# RS1xxxx register map
Vendor: Silicon Lab Inc.; Series: ARMCM4; File version: 1.2
CPU: CM4 r1p0, little endian, MPU, FPU, 6 interrupt priority bits
Registers are 32-bit, read-write, reset 0x0 unless marked. A register's access mark holds for its fields unless they carry their own. Offsets are from the block's base; [hi:lo] are bit positions; lines under a group give offsets from that group; {n}, {i} and the like mark numbered series.

## SDC — Sensor Data Collector Register structure
Base 0x24042400
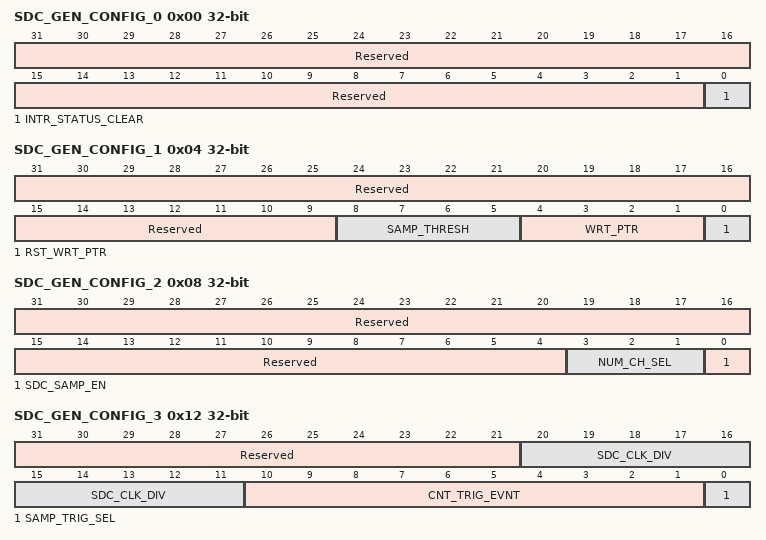
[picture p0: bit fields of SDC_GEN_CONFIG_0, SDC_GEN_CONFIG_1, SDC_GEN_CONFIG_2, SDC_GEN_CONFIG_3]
0x00 SDC_GEN_CONFIG_0 — SDC general configuration 0
  [31:1] Reserved — Reserevd
  [0] INTR_STATUS_CLEAR — Writing 1 clears interrupt, reading gives SDC Interrupt status
0x04 SDC_GEN_CONFIG_1 — SDC general configuration 1
  [31:9] Reserved — Reserevd
  [8:5] SAMP_THRESH — Number of data sampled to be collected from Aux-ADC and stored in Buffer before interrupt is raised/wakeup is initialed
  [4:1] WRT_PTR ro — Write pointer Value
  [0] RST_WRT_PTR — Writing 1 will resets the write pointer so that new samples can be filled in Buffer.
0x08 SDC_GEN_CONFIG_2 — SDC general configuration 2
  [31:4] Reserved — Reserevd
  [3:1] NUM_CH_SEL — Number of Channels to be used
  [0] SDC_SAMP_EN — SDC Data Sampling mode
    1=Enable; 0=Disable
0x12 SDC_GEN_CONFIG_3 — SDC general configuration 3
  [31:21] Reserved — Reserevd
  [20:11] SDC_CLK_DIV — SDCSS clock division factor
  [10:1] CNT_TRIG_EVNT — which trigger event AUX-ADC Data will sampled
    1=Enable; 0=Disable
  [0] SAMP_TRIG_SEL — select the trigger event on which AUX-ADC Data is sampled
    1=Enable; 0=Disable
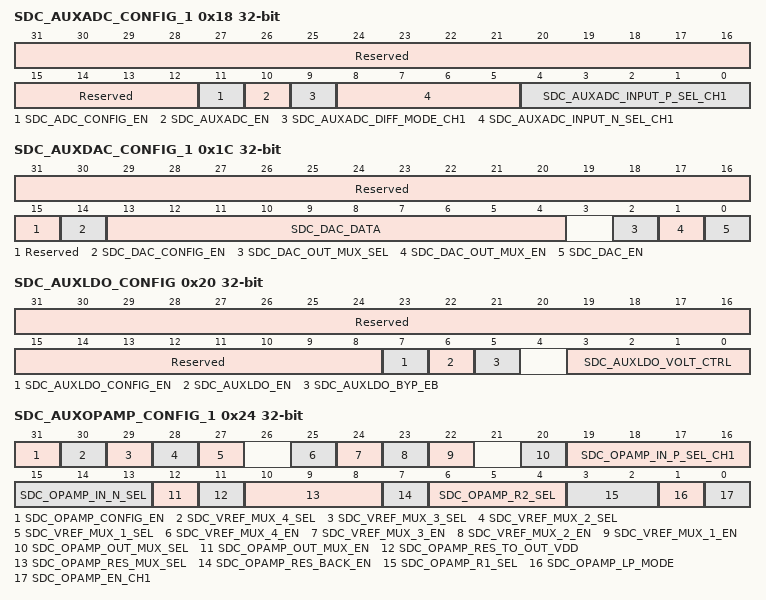
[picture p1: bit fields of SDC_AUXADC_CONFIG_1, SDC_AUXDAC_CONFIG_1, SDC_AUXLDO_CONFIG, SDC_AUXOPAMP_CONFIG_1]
0x18 SDC_AUXADC_CONFIG_1 — SDC AUX ADC configuration 1
  [31:12] Reserved — Reserevd
  [11] SDC_ADC_CONFIG_EN — On Enabling this register, SDC ADC Configuration will be Applied.
  [10] SDC_AUXADC_EN — AUXADC Enable from SDC Block
  [9] SDC_AUXADC_DIFF_MODE_CH1 — Enable Differential Mode in AUX ADC for Channel -1
  [8:5] SDC_AUXADC_INPUT_N_SEL_CH1 — AUXADC's Negative Input Mux Select for Channel-1
  [4:0] SDC_AUXADC_INPUT_P_SEL_CH1 — AUXADC's Positive Input Mux Select for Channel-1
0x1C SDC_AUXDAC_CONFIG_1 — SDC AUX DAC configuration 1
  [31:15] Reserved — Reserevd
  [14] SDC_DAC_CONFIG_EN — On Enabling this register, SDC DAC Configuration will be Applied.
  [13:4] SDC_DAC_DATA — SDC Aux DAC Data
  [2] SDC_DAC_OUT_MUX_SEL — Programming register for choosing GPIO in which DAC Output is connected
  [1] SDC_DAC_OUT_MUX_EN — Enable signal for Connecting DAC Output to GPIO
  [0] SDC_DAC_EN — Enable signal DAC
0x20 SDC_AUXLDO_CONFIG — SDC AUX LDO configuration
  [31:8] Reserved — Reserevd
  [7] SDC_AUXLDO_CONFIG_EN — SDC Aux LDO Configuration Control Enable
  [6] SDC_AUXLDO_EN — Turn-On AUX LDO
  [5] SDC_AUXLDO_BYP_EB — Configure AUXLDO in Buypass mode.When Enabled, Ouput supply of LDO will be same as Input supply.
  [3:0] SDC_AUXLDO_VOLT_CTRL — SDC AUX LDO Voltage Control Selection
0x24 SDC_AUXOPAMP_CONFIG_1 — SDC AUX OPAMP configuration 1
  [31] SDC_OPAMP_CONFIG_EN — On Enabling this register, SDC OPAMP Configuration will be Applied.
  [30] SDC_VREF_MUX_4_SEL — Selection register for choosing Voltage reference to external use on ULP_GPIO_15
  [29] SDC_VREF_MUX_3_SEL — Selection register for choosing Voltage reference to external use on ULP_GPIO_4
  [28] SDC_VREF_MUX_2_SEL — Selection register for choosing Voltage reference to external use on ULP_GPIO_3
  [27] SDC_VREF_MUX_1_SEL — Selection register for choosing Voltage reference to external use on ULP_GPIO_1
  [25] SDC_VREF_MUX_4_EN — Connect Low Drive Strength voltage reference for ULP GPIO 15 For external use
  [24] SDC_VREF_MUX_3_EN — Connect Low Drive Strength voltage reference for ULP GPIO 4 For external use
  [23] SDC_VREF_MUX_2_EN — Connect Low Drive Strength voltage reference for ULP GPIO 3 For external use
  [22] SDC_VREF_MUX_1_EN — Connect Low Drive Strength voltage reference for ULP GPIO 1 For external use
  [20] SDC_OPAMP_OUT_MUX_SEL — Configuration register for connecting OPAMP1 output to GPIO
  [19:16] SDC_OPAMP_IN_P_SEL_CH1 — Configuration register for selecting P Input of OPAMP1.,for CH1
  [15:13] SDC_OPAMP_IN_N_SEL — Configuration register for selecting N Input of OPAMP1.
  [12] SDC_OPAMP_OUT_MUX_EN — Configur this register to OPAMP1 Output will be connected to GPIO
  [11] SDC_OPAMP_RES_TO_OUT_VDD — Configuration register for Connecting R2 Resistor Ladder input
  [10:8] SDC_OPAMP_RES_MUX_SEL — Configuration register for Connecting R1 Resistor Ladder input
  [7] SDC_OPAMP_RES_BACK_EN — Configuration register for controlling Resistor Bank of OPAMP
  [6:4] SDC_OPAMP_R2_SEL — Configuration for Resistor Ladder R2 of OPAMP1 for controlling it gain.
  [3:2] SDC_OPAMP_R1_SEL — Configuration for Resistor Ladder R1 of OPAMP1 for controlling it gain.
  [1] SDC_OPAMP_LP_MODE — Configuration of OPAMP1 Operation mode
  [0] SDC_OPAMP_EN_CH1 — Enable signal for turning OPAMP to used for Channel-1 Operation
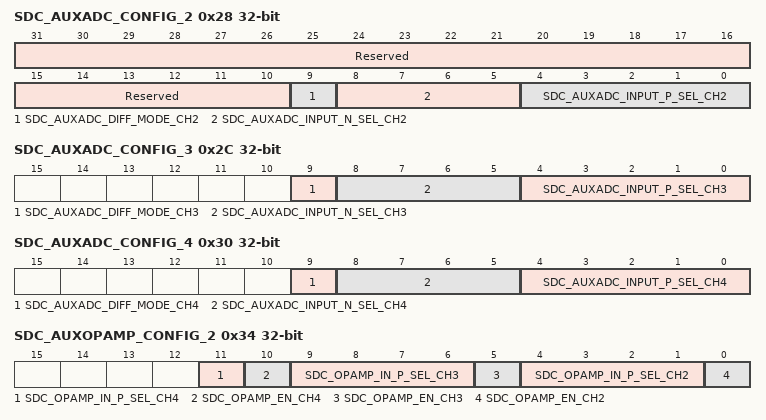
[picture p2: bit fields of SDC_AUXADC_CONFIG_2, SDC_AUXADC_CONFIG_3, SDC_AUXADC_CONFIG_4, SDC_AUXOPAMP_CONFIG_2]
0x28 SDC_AUXADC_CONFIG_2 — SDC AUX ADC configuration 2
  [31:10] Reserved — Reserevd
  [9] SDC_AUXADC_DIFF_MODE_CH2 — 1-AUX ADC Differencial mode, 0 - Single Ended Mode
  [8:5] SDC_AUXADC_INPUT_N_SEL_CH2 — AUXADC's Negative Input Mux Select for Channel-2
  [4:0] SDC_AUXADC_INPUT_P_SEL_CH2 — AUXADC's Positive Input Mux Select for Channel-2
0x2C SDC_AUXADC_CONFIG_3 — SDC AUX ADC configuration 3
  [9] SDC_AUXADC_DIFF_MODE_CH3 — 1-AUX ADC Differencial mode, 0 - Single Ended Mode
  [8:5] SDC_AUXADC_INPUT_N_SEL_CH3 — AUXADC's Negative Input Mux Select for Channel-3
  [4:0] SDC_AUXADC_INPUT_P_SEL_CH3 — AUXADC's Positive Input Mux Select for Channel-3
0x30 SDC_AUXADC_CONFIG_4 — SDC AUX ADC configuration 4
  [9] SDC_AUXADC_DIFF_MODE_CH4 — 1-AUX ADC Differencial mode, 0 - Single Ended Mode
  [8:5] SDC_AUXADC_INPUT_N_SEL_CH4 — AUXADC's Negative Input Mux Select for Channel-4
  [4:0] SDC_AUXADC_INPUT_P_SEL_CH4 — AUXADC's Positive Input Mux Select for Channel-4
0x34 SDC_AUXOPAMP_CONFIG_2 — SDC AUX OPAMP Configuration 2
  [11] SDC_OPAMP_IN_P_SEL_CH4 — Configuration register for selecting P Input of OPAMP1 for Channel-4
  [10] SDC_OPAMP_EN_CH4 — Enable signal for turning OPAMP to used for Channel-4 Operation
  [9:6] SDC_OPAMP_IN_P_SEL_CH3 — Configuration register for selecting P Input of OPAMP1 for Channel-3
  [5] SDC_OPAMP_EN_CH3 — Enable signal for turning OPAMP to used for Channel-4 Operation
  [4:1] SDC_OPAMP_IN_P_SEL_CH2 — Configuration register for selecting P Input of OPAMP1 for Channel-2
  [0] SDC_OPAMP_EN_CH2 — Enable signal for turning OPAMP to used for Channel-2 Operation
{0x38+4i} SDC_DATA_REGn[{i}] (i=0..15) group — SDC Data registers (0-15)
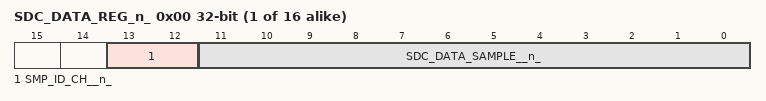
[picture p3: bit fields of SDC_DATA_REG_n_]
  0x00 SDC_DATA_REG_n_ ro reset not defined — SDC Data register _n_
    [13:12] SMP_ID_CH__n_ — Channel iD for sample _n_
    [11:0] SDC_DATA_SAMPLE__n_ — Sample 0 collected from Sensor through Aux ADC.
